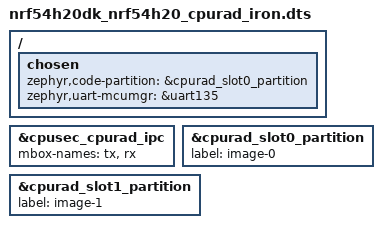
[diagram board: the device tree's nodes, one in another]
/*
 * Copyright (c) 2025 Nordic Semiconductor ASA
 *
 * SPDX-License-Identifier: Apache-2.0
 */

#include "nrf54h20dk_nrf54h20_cpurad.dts"
#include "nrf54h20dk_nrf54h20-ipc_conf_iron.dtsi"
#include "nrf54h20dk_nrf54h20-memory_map_iron.dtsi"

/ {
	chosen {
		zephyr,code-partition = &cpurad_slot0_partition;
		zephyr,uart-mcumgr = &uart135;
	};
};

&cpusec_cpurad_ipc {
	mbox-names = "tx", "rx";
	status = "okay";
};

slot0_partition: &cpurad_slot0_partition {
	label = "image-0";
};

slot1_partition: &cpurad_slot1_partition {
	label = "image-1";
};
